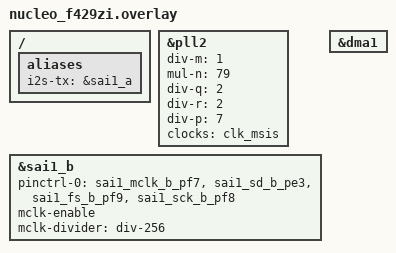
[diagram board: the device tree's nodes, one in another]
/*
 * Copyright (c) 2025 Mario Paja <mariopaja@hotmail.com>
 *
 * SPDX-License-Identifier: Apache-2.0
 */

/ {
	aliases {
		i2s-tx = &sai1_a;
	};
};

&pll2 {
	/* 44.1KHz (-0.03% Error) */
	div-m = <1>;
	mul-n = <79>;
	div-q = <2>;
	div-r = <2>;
	div-p = <7>;
	clocks = <&clk_msis>;
	status = "okay";
};

&sai1_b {
	pinctrl-0 = <&sai1_mclk_b_pf7 &sai1_sd_b_pe3
		&sai1_fs_b_pf9 &sai1_sck_b_pf8>;
	pinctrl-names = "default";
	status = "okay";
	mclk-enable;
	mclk-divider = "div-256";
	dma-names = "tx";
};

&dma1 {
	status = "okay";
};
